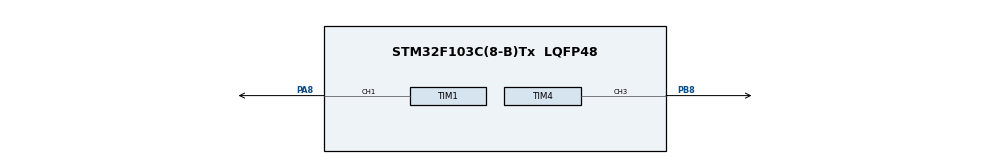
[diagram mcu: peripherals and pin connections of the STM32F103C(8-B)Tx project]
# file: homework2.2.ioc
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Mcu.Family=STM32F1
Mcu.Name=STM32F103C(8-B)Tx
Mcu.Package=LQFP48
NVIC.PriorityGroup=NVIC_PRIORITYGROUP_4
NVIC.TIM1_UP_IRQn=true\:0\:0\:false\:false\:true\:true\:true\:true
PA13.Mode=Serial_Wire
PA13.Signal=SYS_JTMS-SWDIO
PA14.Mode=Serial_Wire
PA14.Signal=SYS_JTCK-SWCLK
PA8.Signal=S_TIM1_CH1
PB8.Signal=S_TIM4_CH3
PD0-OSC_IN.Mode=HSE-External-Oscillator
PD0-OSC_IN.Signal=RCC_OSC_IN
PD1-OSC_OUT.Mode=HSE-External-Oscillator
PD1-OSC_OUT.Signal=RCC_OSC_OUT
ProjectManager.HeapSize=0x200
ProjectManager.StackSize=0x400
ProjectManager.TargetToolchain=MDK-ARM V5.32
RCC.APB1Freq_Value=8000000
RCC.APB2Freq_Value=8000000
SH.S_TIM1_CH1.0=TIM1_CH1,PWM Generation1 CH1
SH.S_TIM4_CH3.0=TIM4_CH3,PWM Generation3 CH3
TIM1.Channel-PWM\ Generation1\ CH1=TIM_CHANNEL_1
TIM1.Period=9999
TIM1.Prescaler=7
TIM4.Channel-PWM\ Generation3\ CH3=TIM_CHANNEL_3
TIM4.Period=19999
TIM4.Prescaler=7
TIM4.Pulse-PWM\ Generation3\ CH3=0
VP_TIM1_VS_ClockSourceINT.Mode=Internal
VP_TIM4_VS_ClockSourceINT.Mode=Internal
board=custom

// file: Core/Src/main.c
/* USER CODE BEGIN Header */
/**
  ******************************************************************************
  * @file           : main.c
  * @brief          : Main program body
  ******************************************************************************
  * @attention
  *
  * Copyright (c) 2026 STMicroelectronics.
  * All rights reserved.
  *
  * This software is licensed under terms that can be found in the LICENSE file
  * in the root directory of this software component.
  * If no LICENSE file comes with this software, it is provided AS-IS.
  *
  ******************************************************************************
  */
/* USER CODE END Header */
#include "main.h"
#include "tim.h"
#include "gpio.h"

/* USER CODE BEGIN Includes */
#include "math.h"
/* USER CODE END Includes */

/* USER CODE BEGIN PV */
volatile uint32_t duty_led = 0;
volatile uint32_t delta = 1;
static volatile uint32_t arr_led;
/* USER CODE END PV */

void SystemClock_Config(void);

/* USER CODE BEGIN 0 */
void HAL_TIM_PeriodElapsedCallback(TIM_HandleTypeDef *htim)
{
  if (htim->Instance == TIM1)
  {
    duty_led += delta;
    uint16_t crr_led = duty_led * (arr_led + 1) / 100;
    __HAL_TIM_SET_COMPARE(&htim1, TIM_CHANNEL_1, crr_led);
    if (duty_led >= 100 || duty_led <= 0)
    {
      delta = -delta;
    }
  }
}
/* USER CODE END 0 */

int main(void)
{

  /* MCU Configuration--------------------------------------------------------*/

  /* Reset of all peripherals, Initializes the Flash interface and the Systick. */
  HAL_Init();

  /* Configure the system clock */
  SystemClock_Config();

  /* Initialize all configured peripherals */
  MX_GPIO_Init();
  MX_TIM1_Init();
  MX_TIM4_Init();
  /* USER CODE BEGIN 2 */
  HAL_TIM_PWM_Start(&htim1, TIM_CHANNEL_1);
	HAL_TIM_Base_Start_IT(&htim1);
  HAL_TIM_PWM_Start(&htim4, TIM_CHANNEL_3);
  /* USER CODE END 2 */

  /* Infinite loop */
  /* USER CODE BEGIN WHILE */
	arr_led = __HAL_TIM_GET_AUTORELOAD(&htim1);
  while (1)
  {
    uint16_t angle = 0;
    for (angle = 0; angle < 180; angle++)
    {
      uint16_t ccr_servo = 500 + angle/180.0 * 2000;
			__HAL_TIM_SET_COMPARE(&htim4, TIM_CHANNEL_3, ccr_servo);
      HAL_Delay(10);
    }
		angle = 180;
    for (angle = 180; angle > 0; angle--)
    {
      uint16_t ccr_servo = 500 + angle/180.0 * 2000;
			__HAL_TIM_SET_COMPARE(&htim4, TIM_CHANNEL_3, ccr_servo);
      HAL_Delay(10);
    }
    /* USER CODE END WHILE */

  }
}

void SystemClock_Config(void)
{
  RCC_OscInitTypeDef RCC_OscInitStruct = {0};
  RCC_ClkInitTypeDef RCC_ClkInitStruct = {0};

  /** Initializes the RCC Oscillators according to the specified parameters
  * in the RCC_OscInitTypeDef structure.
  */
  RCC_OscInitStruct.OscillatorType = RCC_OSCILLATORTYPE_HSI;
  RCC_OscInitStruct.HSIState = RCC_HSI_ON;
  RCC_OscInitStruct.HSICalibrationValue = RCC_HSICALIBRATION_DEFAULT;
  RCC_OscInitStruct.PLL.PLLState = RCC_PLL_NONE;
  if (HAL_RCC_OscConfig(&RCC_OscInitStruct) != HAL_OK)
  {
    Error_Handler();
  }

  /** Initializes the CPU, AHB and APB buses clocks
  */
  RCC_ClkInitStruct.ClockType = RCC_CLOCKTYPE_HCLK|RCC_CLOCKTYPE_SYSCLK
                              |RCC_CLOCKTYPE_PCLK1|RCC_CLOCKTYPE_PCLK2;
  RCC_ClkInitStruct.SYSCLKSource = RCC_SYSCLKSOURCE_HSI;
  RCC_ClkInitStruct.AHBCLKDivider = RCC_SYSCLK_DIV1;
  RCC_ClkInitStruct.APB1CLKDivider = RCC_HCLK_DIV1;
  RCC_ClkInitStruct.APB2CLKDivider = RCC_HCLK_DIV1;

  if (HAL_RCC_ClockConfig(&RCC_ClkInitStruct, FLASH_LATENCY_0) != HAL_OK)
  {
    Error_Handler();
  }
}

void Error_Handler(void)
{
  __disable_irq();
  while (1)
  {
  }
}
